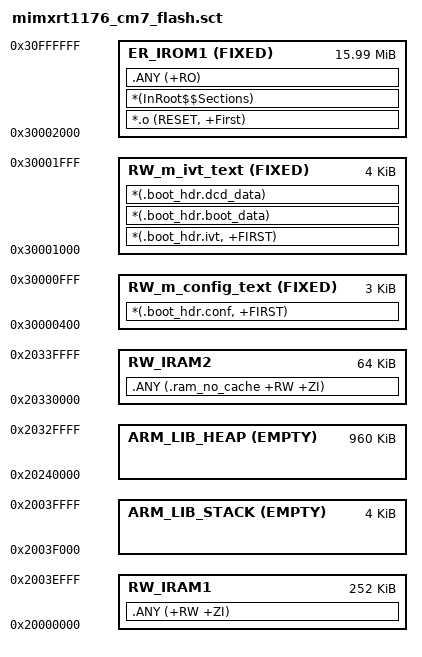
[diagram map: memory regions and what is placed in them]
;******************************************************************
;* i.MX RT1176 linker scatter file (running code from QSPI Flash) *
;******************************************************************

LR_IROM1 0x30000000 0x1000000
{
   RW_m_config_text 0x30000400 FIXED 0xC00
   {
      *(.boot_hdr.conf, +FIRST)
   }
   
   RW_m_ivt_text 0x30001000 FIXED 0x1000
   {
      *(.boot_hdr.ivt, +FIRST)
      *(.boot_hdr.boot_data)
      *(.boot_hdr.dcd_data)
   }
   
   ER_IROM1 0x30002000 FIXED 0xFFE000
   {
      *.o (RESET, +First)
      *(InRoot$$Sections)
      .ANY (+RO)
   }
   
   RW_IRAM1 0x20000000 0x3F000
   {
      .ANY (+RW +ZI)
   }
   
   ARM_LIB_STACK 0x20040000 EMPTY -0x1000
   {
   }
   
   ARM_LIB_HEAP 0x20240000 EMPTY 0xF0000
   {
   }
   
   RW_IRAM2 0x20330000 0x10000
   {
      .ANY (.ram_no_cache +RW +ZI)
   }
}
